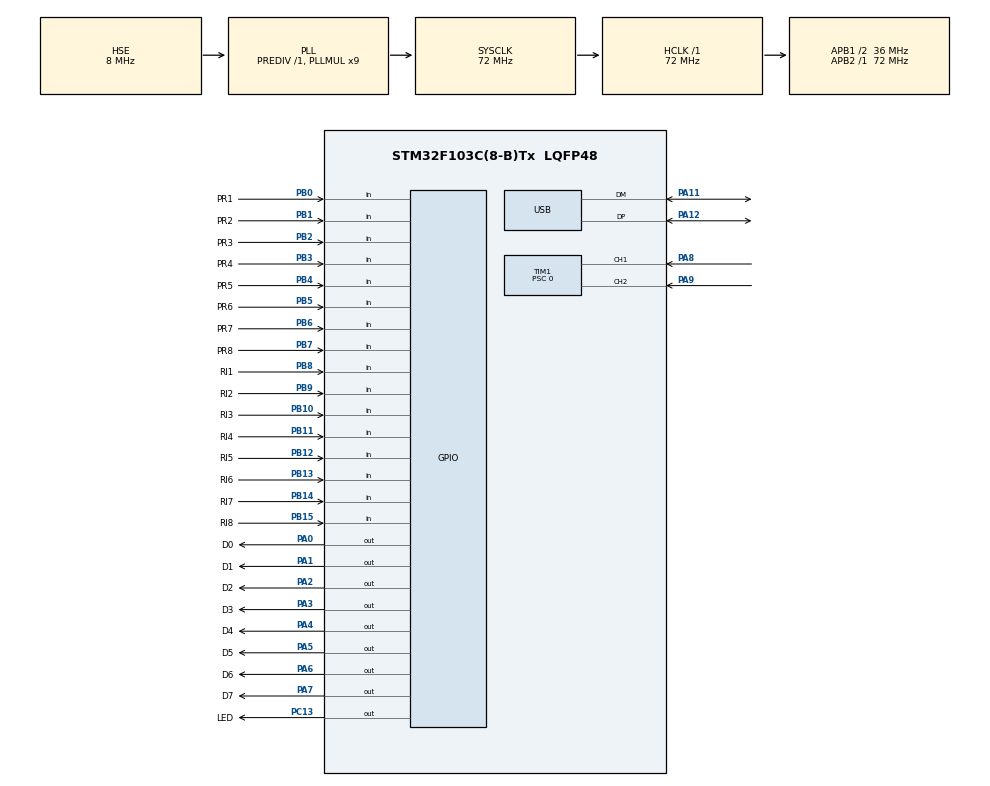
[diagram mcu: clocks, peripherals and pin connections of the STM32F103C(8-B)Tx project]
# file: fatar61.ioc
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Mcu.Family=STM32F1
Mcu.Name=STM32F103C(8-B)Tx
Mcu.Package=LQFP48
NVIC.PriorityGroup=NVIC_PRIORITYGROUP_4
NVIC.TIM2_IRQn=true\:0\:0\:false\:false\:true\:true\:true
NVIC.USB_LP_CAN1_RX0_IRQn=true\:0\:0\:false\:false\:true\:false\:true
PA0-WKUP.GPIO_Label=D0
PA0-WKUP.Signal=GPIO_Output
PA1.GPIO_Label=D1
PA1.Signal=GPIO_Output
PA11.Mode=Device
PA11.Signal=USB_DM
PA12.Mode=Device
PA12.Signal=USB_DP
PA13.Mode=Serial_Wire
PA13.Signal=SYS_JTMS-SWDIO
PA14.Mode=Serial_Wire
PA14.Signal=SYS_JTCK-SWCLK
PA2.GPIO_Label=D2
PA2.Signal=GPIO_Output
PA3.GPIO_Label=D3
PA3.Signal=GPIO_Output
PA4.GPIO_Label=D4
PA4.Signal=GPIO_Output
PA5.GPIO_Label=D5
PA5.Signal=GPIO_Output
PA6.GPIO_Label=D6
PA6.Signal=GPIO_Output
PA7.GPIO_Label=D7
PA7.Signal=GPIO_Output
PA8.Signal=S_TIM1_CH1
PA9.Signal=S_TIM1_CH2
PB0.GPIO_Label=PR1
PB0.GPIO_PuPd=GPIO_PULLDOWN
PB0.Signal=GPIO_Input
PB1.GPIO_Label=PR2
PB1.GPIO_PuPd=GPIO_PULLDOWN
PB1.Signal=GPIO_Input
PB10.GPIO_Label=RI3
PB10.GPIO_PuPd=GPIO_PULLDOWN
PB10.Signal=GPIO_Input
PB11.GPIO_Label=RI4
PB11.GPIO_PuPd=GPIO_PULLDOWN
PB11.Signal=GPIO_Input
PB12.GPIO_Label=RI5
PB12.GPIO_PuPd=GPIO_PULLDOWN
PB12.Signal=GPIO_Input
PB13.GPIO_Label=RI6
PB13.GPIO_PuPd=GPIO_PULLDOWN
PB13.Signal=GPIO_Input
PB14.GPIO_Label=RI7
PB14.GPIO_PuPd=GPIO_PULLDOWN
PB14.Signal=GPIO_Input
PB15.GPIO_Label=RI8
PB15.GPIO_PuPd=GPIO_PULLDOWN
PB15.Signal=GPIO_Input
PB2.GPIO_Label=PR3
PB2.GPIO_PuPd=GPIO_PULLDOWN
PB2.Signal=GPIO_Input
PB3.GPIO_Label=PR4
PB3.GPIO_PuPd=GPIO_PULLDOWN
PB3.Signal=GPIO_Input
PB4.GPIO_Label=PR5
PB4.GPIO_PuPd=GPIO_PULLDOWN
PB4.Signal=GPIO_Input
PB5.GPIO_Label=PR6
PB5.GPIO_PuPd=GPIO_PULLDOWN
PB5.Signal=GPIO_Input
PB6.GPIO_Label=PR7
PB6.GPIO_PuPd=GPIO_PULLDOWN
PB6.Signal=GPIO_Input
PB7.GPIO_Label=PR8
PB7.GPIO_PuPd=GPIO_PULLDOWN
PB7.Signal=GPIO_Input
PB8.GPIO_Label=RI1
PB8.GPIO_PuPd=GPIO_PULLDOWN
PB8.Signal=GPIO_Input
PB9.GPIO_Label=RI2
PB9.GPIO_PuPd=GPIO_PULLDOWN
PB9.Signal=GPIO_Input
PC13-TAMPER-RTC.GPIO_Label=LED
PC13-TAMPER-RTC.Signal=GPIO_Output
PC14-OSC32_IN.Mode=LSE-External-Oscillator
PC14-OSC32_IN.Signal=RCC_OSC32_IN
PC15-OSC32_OUT.Mode=LSE-External-Oscillator
PC15-OSC32_OUT.Signal=RCC_OSC32_OUT
PD0-OSC_IN.Mode=HSE-External-Oscillator
PD0-OSC_IN.Signal=RCC_OSC_IN
PD1-OSC_OUT.Mode=HSE-External-Oscillator
PD1-OSC_OUT.Signal=RCC_OSC_OUT
ProjectManager.HeapSize=0x200
ProjectManager.StackSize=0x400
ProjectManager.TargetToolchain=STM32CubeIDE
RCC.AHBFreq_Value=72000000
RCC.APB1CLKDivider=RCC_HCLK_DIV2
RCC.APB1Freq_Value=36000000
RCC.APB1TimFreq_Value=72000000
RCC.APB2Freq_Value=72000000
RCC.APB2TimFreq_Value=72000000
RCC.HCLKFreq_Value=72000000
RCC.PLLMUL=RCC_PLL_MUL9
RCC.SYSCLKFreq_VALUE=72000000
RCC.SYSCLKSource=RCC_SYSCLKSOURCE_PLLCLK
RCC.USBFreq_Value=48000000
RCC.USBPrescaler=RCC_USBCLKSOURCE_PLL_DIV1_5
SH.S_TIM1_CH1.0=TIM1_CH1,Encoder_Interface
SH.S_TIM1_CH2.0=TIM1_CH2,Encoder_Interface
TIM1.AutoReloadPreload=TIM_AUTORELOAD_PRELOAD_ENABLE
TIM1.EncoderMode=TIM_ENCODERMODE_TI12
TIM1.IC1Filter=10
TIM1.Period=0xffff-1
TIM1.Prescaler=0
TIM2.AutoReloadPreload=TIM_AUTORELOAD_PRELOAD_ENABLE
TIM2.ClockDivision=TIM_CLOCKDIVISION_DIV1
TIM2.Period=1000-1
TIM2.Prescaler=72-1
USB_DEVICE.CLASS_NAME_FS=AUDIO
USB_DEVICE.VirtualMode=Audio
USB_DEVICE.VirtualModeFS=Audio_FS
VP_TIM2_VS_ClockSourceINT.Mode=Internal
VP_USB_DEVICE_VS_USB_DEVICE_AUDIO_FS.Mode=AUDIO_FS
board=custom

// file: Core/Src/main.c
/* USER CODE BEGIN Header */
/**
  ******************************************************************************
  * @file           : main.c
  * @brief          : Main program body
  ******************************************************************************
  * @attention
  *
  * <h2><center>&copy; Copyright (c) 2021 STMicroelectronics.
  * All rights reserved.</center></h2>
  *
  * This software component is licensed by ST under BSD 3-Clause license,
  * the "License"; You may not use this file except in compliance with the
  * License. You may obtain a copy of the License at:
  *                        opensource.org/licenses/BSD-3-Clause
  *
  ******************************************************************************
  */
/* USER CODE END Header */
#include "main.h"
#include "usb_device.h"

/* USER CODE BEGIN Includes */
#include "startup.h"
#include "usb_device.h"
#include "usbd_midi_if.h"
/* USER CODE END Includes */

TIM_HandleTypeDef htim1;
TIM_HandleTypeDef htim2;

void SystemClock_Config(void);
static void MX_GPIO_Init(void);
static void MX_TIM1_Init(void);
static void MX_TIM2_Init(void);

/* USER CODE BEGIN 0 */
//#ifdef __GNUC__
//#define PUTCHAR_PROTOTYPE int __io_putchar(int ch)
//#else
//#define PUTCHAR_PROTOTYPE int fputc(int ch, FILE *f)
//#endif /* __GNUC__ */
//
///**
//  * @brief  Retargets the C library printf function to the USART.
//  * @param  None
//  * @retval None
//  */
//PUTCHAR_PROTOTYPE
//{
//  HAL_UART_Transmit(&huart1, (uint8_t *)&ch, 1, 100);
//  return ch;
//}

/* USER CODE END 0 */

int main(void)
{

  /* MCU Configuration--------------------------------------------------------*/

  /* Reset of all peripherals, Initializes the Flash interface and the Systick. */
  HAL_Init();

  /* Configure the system clock */
  SystemClock_Config();

  /* Initialize all configured peripherals */
  MX_GPIO_Init();
  MX_TIM1_Init();
  MX_TIM2_Init();
  MX_USB_DEVICE_Init();

  /* Infinite loop */
  /* USER CODE BEGIN WHILE */
  initialize();
  while (1)
  {
	  loop();
    /* USER CODE END WHILE */

  }
}

void SystemClock_Config(void)
{
  RCC_OscInitTypeDef RCC_OscInitStruct = {0};
  RCC_ClkInitTypeDef RCC_ClkInitStruct = {0};
  RCC_PeriphCLKInitTypeDef PeriphClkInit = {0};

  /** Initializes the RCC Oscillators according to the specified parameters
  * in the RCC_OscInitTypeDef structure.
  */
  RCC_OscInitStruct.OscillatorType = RCC_OSCILLATORTYPE_HSE;
  RCC_OscInitStruct.HSEState = RCC_HSE_ON;
  RCC_OscInitStruct.HSEPredivValue = RCC_HSE_PREDIV_DIV1;
  RCC_OscInitStruct.HSIState = RCC_HSI_ON;
  RCC_OscInitStruct.PLL.PLLState = RCC_PLL_ON;
  RCC_OscInitStruct.PLL.PLLSource = RCC_PLLSOURCE_HSE;
  RCC_OscInitStruct.PLL.PLLMUL = RCC_PLL_MUL9;
  if (HAL_RCC_OscConfig(&RCC_OscInitStruct) != HAL_OK)
  {
    Error_Handler();
  }
  /** Initializes the CPU, AHB and APB buses clocks
  */
  RCC_ClkInitStruct.ClockType = RCC_CLOCKTYPE_HCLK|RCC_CLOCKTYPE_SYSCLK
                              |RCC_CLOCKTYPE_PCLK1|RCC_CLOCKTYPE_PCLK2;
  RCC_ClkInitStruct.SYSCLKSource = RCC_SYSCLKSOURCE_PLLCLK;
  RCC_ClkInitStruct.AHBCLKDivider = RCC_SYSCLK_DIV1;
  RCC_ClkInitStruct.APB1CLKDivider = RCC_HCLK_DIV2;
  RCC_ClkInitStruct.APB2CLKDivider = RCC_HCLK_DIV1;

  if (HAL_RCC_ClockConfig(&RCC_ClkInitStruct, FLASH_LATENCY_2) != HAL_OK)
  {
    Error_Handler();
  }
  PeriphClkInit.PeriphClockSelection = RCC_PERIPHCLK_USB;
  PeriphClkInit.UsbClockSelection = RCC_USBCLKSOURCE_PLL_DIV1_5;
  if (HAL_RCCEx_PeriphCLKConfig(&PeriphClkInit) != HAL_OK)
  {
    Error_Handler();
  }
}

static void MX_TIM1_Init(void)
{

  TIM_Encoder_InitTypeDef sConfig = {0};
  TIM_MasterConfigTypeDef sMasterConfig = {0};

  htim1.Instance = TIM1;
  htim1.Init.Prescaler = 0;
  htim1.Init.CounterMode = TIM_COUNTERMODE_UP;
  htim1.Init.Period = 0xffff-1;
  htim1.Init.ClockDivision = TIM_CLOCKDIVISION_DIV1;
  htim1.Init.RepetitionCounter = 0;
  htim1.Init.AutoReloadPreload = TIM_AUTORELOAD_PRELOAD_ENABLE;
  sConfig.EncoderMode = TIM_ENCODERMODE_TI12;
  sConfig.IC1Polarity = TIM_ICPOLARITY_RISING;
  sConfig.IC1Selection = TIM_ICSELECTION_DIRECTTI;
  sConfig.IC1Prescaler = TIM_ICPSC_DIV1;
  sConfig.IC1Filter = 10;
  sConfig.IC2Polarity = TIM_ICPOLARITY_RISING;
  sConfig.IC2Selection = TIM_ICSELECTION_DIRECTTI;
  sConfig.IC2Prescaler = TIM_ICPSC_DIV1;
  sConfig.IC2Filter = 0;
  if (HAL_TIM_Encoder_Init(&htim1, &sConfig) != HAL_OK)
  {
    Error_Handler();
  }
  sMasterConfig.MasterOutputTrigger = TIM_TRGO_RESET;
  sMasterConfig.MasterSlaveMode = TIM_MASTERSLAVEMODE_DISABLE;
  if (HAL_TIMEx_MasterConfigSynchronization(&htim1, &sMasterConfig) != HAL_OK)
  {
    Error_Handler();
  }

}

static void MX_TIM2_Init(void)
{

  TIM_ClockConfigTypeDef sClockSourceConfig = {0};
  TIM_MasterConfigTypeDef sMasterConfig = {0};

  htim2.Instance = TIM2;
  htim2.Init.Prescaler = 72-1;
  htim2.Init.CounterMode = TIM_COUNTERMODE_UP;
  htim2.Init.Period = 1000-1;
  htim2.Init.ClockDivision = TIM_CLOCKDIVISION_DIV1;
  htim2.Init.AutoReloadPreload = TIM_AUTORELOAD_PRELOAD_ENABLE;
  if (HAL_TIM_Base_Init(&htim2) != HAL_OK)
  {
    Error_Handler();
  }
  sClockSourceConfig.ClockSource = TIM_CLOCKSOURCE_INTERNAL;
  if (HAL_TIM_ConfigClockSource(&htim2, &sClockSourceConfig) != HAL_OK)
  {
    Error_Handler();
  }
  sMasterConfig.MasterOutputTrigger = TIM_TRGO_RESET;
  sMasterConfig.MasterSlaveMode = TIM_MASTERSLAVEMODE_DISABLE;
  if (HAL_TIMEx_MasterConfigSynchronization(&htim2, &sMasterConfig) != HAL_OK)
  {
    Error_Handler();
  }

}

static void MX_GPIO_Init(void)
{
  GPIO_InitTypeDef GPIO_InitStruct = {0};

  /* GPIO Ports Clock Enable */
  __HAL_RCC_GPIOC_CLK_ENABLE();
  __HAL_RCC_GPIOD_CLK_ENABLE();
  __HAL_RCC_GPIOA_CLK_ENABLE();
  __HAL_RCC_GPIOB_CLK_ENABLE();

  /*Configure GPIO pin Output Level */
  HAL_GPIO_WritePin(LED_GPIO_Port, LED_Pin, GPIO_PIN_RESET);

  /*Configure GPIO pin Output Level */
  HAL_GPIO_WritePin(GPIOA, D0_Pin|D1_Pin|D2_Pin|D3_Pin
                          |D4_Pin|D5_Pin|D6_Pin|D7_Pin, GPIO_PIN_RESET);

  /*Configure GPIO pin : LED_Pin */
  GPIO_InitStruct.Pin = LED_Pin;
  GPIO_InitStruct.Mode = GPIO_MODE_OUTPUT_PP;
  GPIO_InitStruct.Pull = GPIO_NOPULL;
  GPIO_InitStruct.Speed = GPIO_SPEED_FREQ_LOW;
  HAL_GPIO_Init(LED_GPIO_Port, &GPIO_InitStruct);

  /*Configure GPIO pins : D0_Pin D1_Pin D2_Pin D3_Pin
                           D4_Pin D5_Pin D6_Pin D7_Pin */
  GPIO_InitStruct.Pin = D0_Pin|D1_Pin|D2_Pin|D3_Pin
                          |D4_Pin|D5_Pin|D6_Pin|D7_Pin;
  GPIO_InitStruct.Mode = GPIO_MODE_OUTPUT_PP;
  GPIO_InitStruct.Pull = GPIO_NOPULL;
  GPIO_InitStruct.Speed = GPIO_SPEED_FREQ_LOW;
  HAL_GPIO_Init(GPIOA, &GPIO_InitStruct);

  /*Configure GPIO pins : PR1_Pin PR2_Pin PR3_Pin RI3_Pin
                           RI4_Pin RI5_Pin RI6_Pin RI7_Pin
                           RI8_Pin PR4_Pin PR5_Pin PR6_Pin
                           PR7_Pin PR8_Pin RI1_Pin RI2_Pin */
  GPIO_InitStruct.Pin = PR1_Pin|PR2_Pin|PR3_Pin|RI3_Pin
                          |RI4_Pin|RI5_Pin|RI6_Pin|RI7_Pin
                          |RI8_Pin|PR4_Pin|PR5_Pin|PR6_Pin
                          |PR7_Pin|PR8_Pin|RI1_Pin|RI2_Pin;
  GPIO_InitStruct.Mode = GPIO_MODE_INPUT;
  GPIO_InitStruct.Pull = GPIO_PULLDOWN;
  HAL_GPIO_Init(GPIOB, &GPIO_InitStruct);

}

void Error_Handler(void)
{
  __disable_irq();
  while (1)
  {
  }
}

/************************ (C) COPYRIGHT STMicroelectronics *****END OF FILE****/
